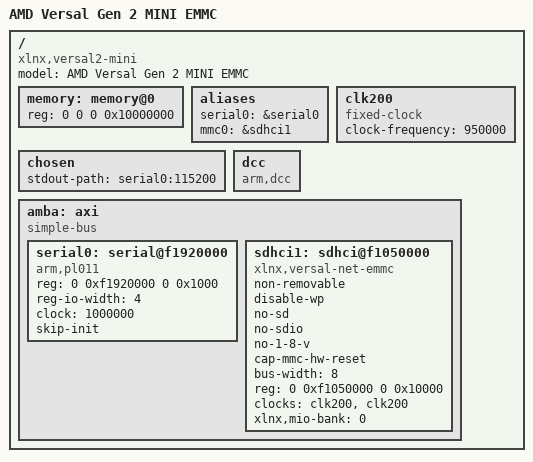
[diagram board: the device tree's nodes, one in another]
// SPDX-License-Identifier: GPL-2.0
/*
 * dts file for AMD Versal Gen2 mini emmc
 *
 * Copyright (C) 2023 - 2024, Advanced Micro Devices, Inc.
 *
 * Michal Simek <michal.simek@amd.com>
 */

/dts-v1/;

#include <dt-bindings/gpio/gpio.h>

/ {
	compatible = "xlnx,versal2-mini";
	model = "AMD Versal Gen 2 MINI EMMC";
	#address-cells = <2>;
	#size-cells = <2>;

	memory: memory@0 {
		reg = <0 0 0 0x10000000>;
		device_type = "memory";
	};

	aliases {
		serial0 = &serial0;
		mmc0 = &sdhci1;
		/* serial0 = &dcc; */
	};

	chosen {
		stdout-path = "serial0:115200";
	};

	clk200: clk200 {
		compatible = "fixed-clock";
		#clock-cells = <0>;
		clock-frequency = <950000>;
	};

	dcc: dcc {
		compatible = "arm,dcc";
		status = "okay";
		bootph-all;
	};

	amba: axi {
		compatible = "simple-bus";
		bootph-all;
		#address-cells = <2>;
		#size-cells = <2>;
		ranges;

		serial0: serial@f1920000 {
			bootph-all;
			compatible = "arm,pl011", "arm,primecell";
			reg = <0 0xf1920000 0 0x1000>;
			reg-io-width = <4>;
			clock = <1000000>;
			skip-init;
		};

		sdhci1: sdhci@f1050000 {
			compatible = "xlnx,versal-net-emmc";
			status = "okay";
			non-removable;
			disable-wp;
			no-sd;
			no-sdio;
			no-1-8-v;
			cap-mmc-hw-reset;
			bus-width = <8>;
			reg = <0 0xf1050000 0 0x10000>;
			clock-names = "clk_xin", "clk_ahb";
			clocks = <&clk200>, <&clk200>;
			xlnx,mio-bank = <0>;
		};
	};
};
